VERSION ""

NS_ :

BS_:

BU_:

BO_ 2147516416 Engine: 4 Vector__XXX
 SG_ RPM : 0|32@1- (1,0) [0|0] "rpm" Vector__XXX

BO_ 2183135233 FR_TieRod: 4 Vector__XXX
 SG_ Strain : 0|32@1- (0.00352091255202,0) [0|0] "lbf" Vector__XXX

BO_ 2218795008 FL_Suspension: 4 Vector__XXX
 SG_ Displacement : 0|32@1- (1,0) [0|0] "" Vector__XXX

BO_ 2183135232 FR_Suspension: 4 Vector__XXX
 SG_ Displacement : 0|32@1- (1,0) [0|0] "" Vector__XXX

BO_ 2218795009 FL_TieRod: 4 Vector__XXX
 SG_ Strain : 0|32@1- (0.00361499518688,0) [0|0] "lbf" Vector__XXX

BO_ 2147516417 WheelSpeed: 4 Vector__XXX
 SG_ RPM : 0|32@1- (1,0) [0|0] "rpm" Vector__XXX

BO_ 2254454784 RR_Suspension: 4 Vector__XXX
 SG_ Displacement : 0|32@1- (1,0) [0|0] "" Vector__XXX

BO_ 2290114560 RL_Suspension: 4 Vector__XXX
 SG_ Displacement : 0|32@1- (1,0) [0|0] "" Vector__XXX

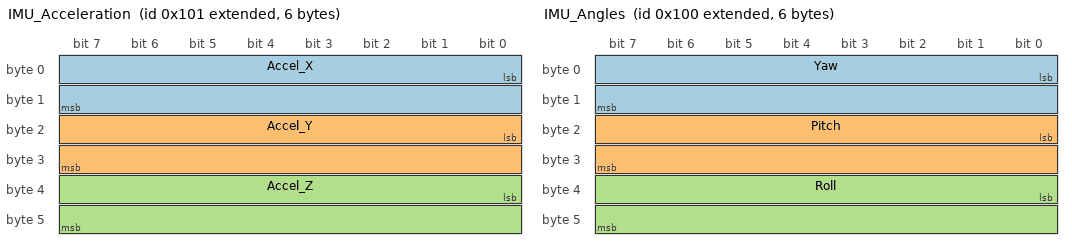
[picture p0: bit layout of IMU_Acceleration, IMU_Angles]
BO_ 2147483905 IMU_Acceleration: 6 Vector__XXX
 SG_ Accel_X : 0|16@1- (0.001,0) [0|0] "m/s^2" Vector__XXX
 SG_ Accel_Y : 16|16@1- (0.001,0) [0|0] "m/s^2" Vector__XXX
 SG_ Accel_Z : 32|16@1- (0.001,0) [0|0] "m/s^2" Vector__XXX

BO_ 2147483904 IMU_Angles: 6 Vector__XXX
 SG_ Yaw : 0|16@1- (0.001,0) [0|0] "degrees" Vector__XXX
 SG_ Pitch : 16|16@1- (0.001,0) [0|0] "degrees" Vector__XXX
 SG_ Roll : 32|16@1- (0.001,0) [0|0] "degrees" Vector__XXX

BA_DEF_  "BusType" STRING ;
BA_DEF_DEF_  "BusType" "CAN";
SIG_VALTYPE_ 2147516416 RPM : 1;
SIG_VALTYPE_ 2218795008 Displacement : 1;
SIG_VALTYPE_ 2183135232 Displacement : 1;
SIG_VALTYPE_ 2147516417 RPM : 1;
SIG_VALTYPE_ 2254454784 Displacement : 1;
SIG_VALTYPE_ 2290114560 Displacement : 1;
